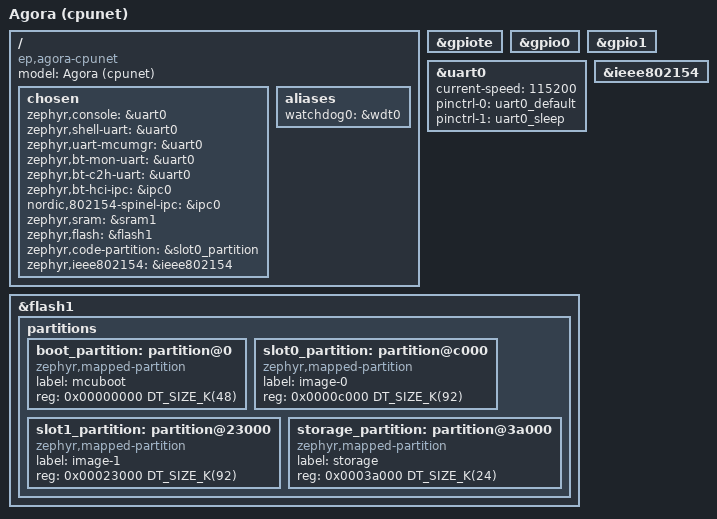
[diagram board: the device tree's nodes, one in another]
/dts-v1/;
#include <arm/nordic/nrf5340_cpunet_qkaa.dtsi>
#include "agora_common.dtsi"
#include "agora_cpunet_pinctrl.dtsi"
#include <zephyr/dt-bindings/input/input-event-codes.h>

/ {
	model = "Agora (cpunet)";
	compatible = "ep,agora-cpunet";

	chosen {
		zephyr,console = &uart0;
		zephyr,shell-uart = &uart0;
		zephyr,uart-mcumgr = &uart0;
		zephyr,bt-mon-uart = &uart0;
		zephyr,bt-c2h-uart = &uart0;
		zephyr,bt-hci-ipc = &ipc0;
		nordic,802154-spinel-ipc = &ipc0;
		zephyr,sram = &sram1;
		zephyr,flash = &flash1;
		zephyr,code-partition = &slot0_partition;
		zephyr,ieee802154 = &ieee802154;
	};

	/* These aliases are provided for compatibility with samples */
	aliases {
		watchdog0 = &wdt0;
	};
};

&gpiote {
	status = "okay";
};

&gpio0 {
	status = "okay";
};

&gpio1 {
	status = "okay";
};

&uart0 {
	status = "okay";
	current-speed = <115200>;
	pinctrl-0 = <&uart0_default>;
	pinctrl-1 = <&uart0_sleep>;
	pinctrl-names = "default", "sleep";
};

&flash1 {
 	partitions {
 		#address-cells = <1>;
 		#size-cells = <1>;
		ranges;

 		boot_partition: partition@0 {
			compatible = "zephyr,mapped-partition";
 			label = "mcuboot";
 			reg = <0x00000000 DT_SIZE_K(48)>;
 		};

 		slot0_partition: partition@c000 {
			compatible = "zephyr,mapped-partition";
 			label = "image-0"; 			reg = <0x0000c000 DT_SIZE_K(92)>;
 		};

 		slot1_partition: partition@23000 {
			compatible = "zephyr,mapped-partition";
 			label = "image-1";
 			reg = <0x00023000 DT_SIZE_K(92)>;
 		};

 		storage_partition: partition@3a000 {
			compatible = "zephyr,mapped-partition";
 			label = "storage";
 			reg = <0x0003a000 DT_SIZE_K(24)>;
 		};
 	};
 };

&ieee802154 {
	status = "okay";
};

#include "agora_shared_sram.dtsi"
